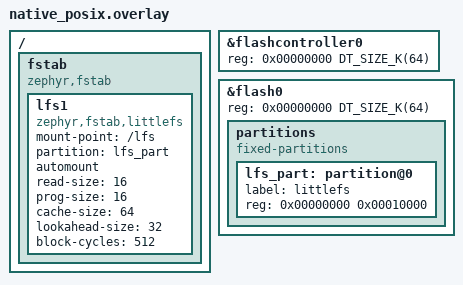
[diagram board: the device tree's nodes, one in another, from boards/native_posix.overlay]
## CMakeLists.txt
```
# SPDX-License-Identifier: Apache-2.0

cmake_minimum_required(VERSION 3.20.0)
find_package(Zephyr REQUIRED HINTS $ENV{ZEPHYR_BASE})
project(littlefs)

# LittleFS opens files for RW by default if no flags given and crashes,
# instead of returning error when attempting to perform operation that
# a file has not been opened for.
target_compile_definitions(app PRIVATE
		BYPASS_FS_OPEN_FLAGS_LFS_ASSERT_CRASH
		BYPASS_FS_OPEN_FLAGS_LFS_RW_IS_DEFAULT
)

FILE(GLOB app_sources src/*.c)
target_sources(app PRIVATE ${app_sources})
```

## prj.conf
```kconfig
CONFIG_FILE_SYSTEM=y
CONFIG_FILE_SYSTEM_LITTLEFS=y

CONFIG_MAIN_STACK_SIZE=4096

CONFIG_FLASH=y
CONFIG_FLASH_MAP=y
CONFIG_FLASH_PAGE_LAYOUT=y

CONFIG_ZTEST=y
CONFIG_ZTEST_STACKSIZE=4096
```

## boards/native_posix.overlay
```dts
/*
 * Copyright (c) 2021 SILA Embedded Solutions GmbH <office@embedded-solutions.at>
 *
 * SPDX-License-Identifier: Apache-2.0
 */

&flashcontroller0 {
	reg = <0x00000000 DT_SIZE_K(64)>;
};

/ {
	fstab {
		compatible = "zephyr,fstab";
		lfs1: lfs1 {
			compatible = "zephyr,fstab,littlefs";
			mount-point = "/lfs";
			partition = <&lfs_part>;
			automount;
			read-size = <16>;
			prog-size = <16>;
			cache-size = <64>;
			lookahead-size = <32>;
			block-cycles = <512>;
		};
	};
};

&flash0 {
	reg = <0x00000000 DT_SIZE_K(64)>;
	partitions {
		compatible = "fixed-partitions";
		#address-cells = <1>;
		#size-cells = <1>;

		lfs_part: partition@0 {
			label = "littlefs";
			reg = <0x00000000 0x00010000>;
		};
	};
};
```

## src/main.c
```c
/*
 * Copyright (c) 2021 SILA Embedded Solutions GmbH <office@embedded-solutions.at>
 *
 * SPDX-License-Identifier: Apache-2.0
 */

#include <string.h>
#include <ztest.h>
#include "test_littlefs_automount.h"

void test_main(void)
{
	ztest_test_suite(littlefs_automount_test,
			 ztest_unit_test(test_automount_opendir),
			 ztest_unit_test(test_automount_check_mounted)
			 );
	ztest_run_test_suite(littlefs_automount_test);
}
```

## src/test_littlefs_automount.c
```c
/*
 * Copyright (c) 2021 SILA Embedded Solutions GmbH <office@embedded-solutions.at>
 *
 * SPDX-License-Identifier: Apache-2.0
 */

#include <zephyr.h>
#include <string.h>
#include <errno.h>
#include <sys/__assert.h>
#include <ztest.h>
#include <fs/fs.h>
#include <fs/fs_sys.h>
#include "test_littlefs_automount.h"

#define DT_DRV_COMPAT zephyr_fstab_littlefs
#define FSTAB_ENTRY_FROM_INST(inst) (&FS_FSTAB_ENTRY(DT_DRV_INST(inst))),
#define FSTAB_ENTRY_DECLARE_FROM_INST(inst) FS_FSTAB_DECLARE_ENTRY(DT_DRV_INST(inst));

DT_INST_FOREACH_STATUS_OKAY(FSTAB_ENTRY_DECLARE_FROM_INST)

static struct fs_mount_t *lfs_partitions[] = {
	DT_INST_FOREACH_STATUS_OKAY(FSTAB_ENTRY_FROM_INST)
};

void test_automount_opendir(void)
{
	int ret;
	struct fs_dir_t directory;
	struct fs_mount_t *mount_point = lfs_partitions[0];

	fs_dir_t_init(&directory);
	ret = fs_opendir(&directory, mount_point->mnt_point);
	zassert_equal(ret, 0, "failed to open directory of mount point");
}

void test_automount_check_mounted(void)
{
	int ret;
	struct fs_mount_t *mount_point;

	mount_point = lfs_partitions[0];

	ret = fs_unmount(mount_point);
	zassert_equal(ret, 0, "failed to unmount lfs");

	ret = fs_mount(mount_point);
	zassert_equal(ret, 0, "failed to re-mount lfs");
}
```

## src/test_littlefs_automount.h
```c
/*
 * Copyright (c) 2021 SILA Embedded Solutions GmbH <office@embedded-solutions.at>
 *
 * SPDX-License-Identifier: Apache-2.0
 */

#ifndef _ZEPHYR_TESTS_SUBSYS_FS_LITTLEFS_AUTOMOUNT_TEST_LITTLEFS_AUTOMOUNT_H_
#define  _ZEPHYR_TESTS_SUBSYS_FS_LITTLEFS_AUTOMOUNT_TEST_LITTLEFS_AUTOMOUNT_H_

void test_automount_opendir(void);
void test_automount_check_mounted(void);

#endif /* _ZEPHYR_TESTS_SUBSYS_FS_LITTLEFS_AUTOMOUNT_TEST_LITTLEFS_AUTOMOUNT_H_ */
```
